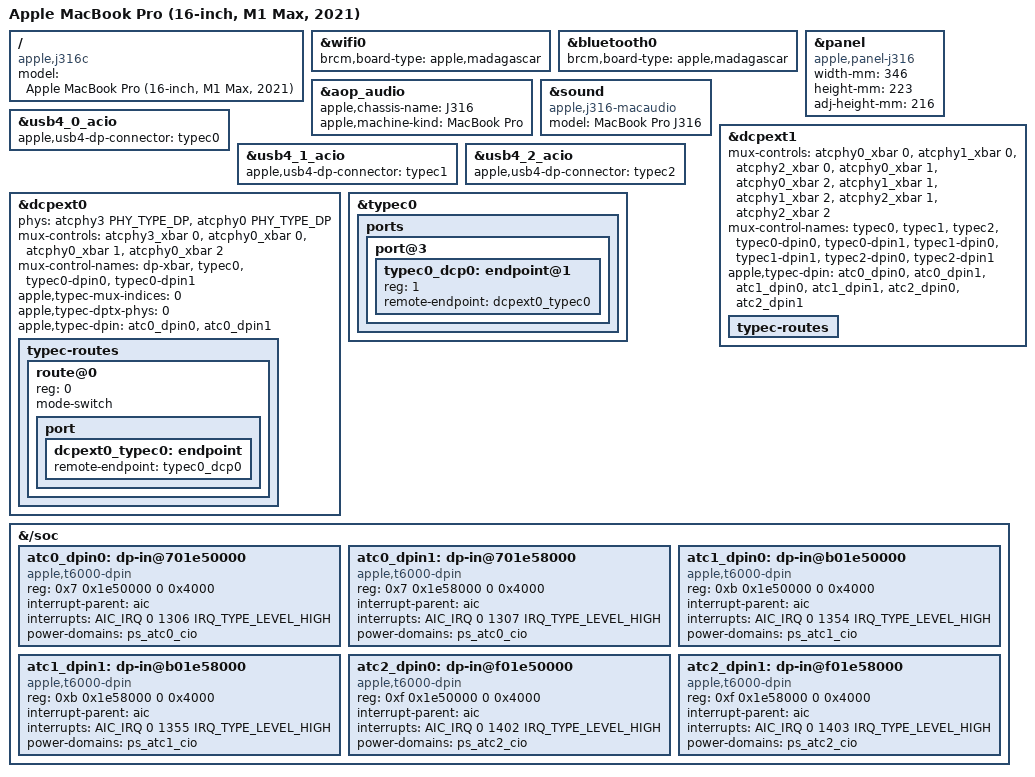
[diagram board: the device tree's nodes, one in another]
// SPDX-License-Identifier: GPL-2.0+ OR MIT
/*
 * MacBook Pro (16-inch, M1 Max, 2021)
 *
 * target-type: J316c
 *
 * Copyright The Asahi Linux Contributors
 */

/dts-v1/;

#include "t6001.dtsi"
#include "t600x-j314-j316.dtsi"

/ {
	compatible = "apple,j316c", "apple,t6001", "apple,arm-platform";
	model = "Apple MacBook Pro (16-inch, M1 Max, 2021)";
};

&wifi0 {
	brcm,board-type = "apple,madagascar";
};

&bluetooth0 {
	brcm,board-type = "apple,madagascar";
};

&panel {
	compatible = "apple,panel-j316", "apple,panel-mini-led", "apple,panel";
	width-mm = <346>;
	height-mm = <223>;
	adj-height-mm = <216>;
};

&aop_audio {
	apple,chassis-name = "J316";
	apple,machine-kind = "MacBook Pro";
};

&sound {
	compatible = "apple,j316-macaudio", "apple,macaudio";
	model = "MacBook Pro J316";
};

/* Experimental USB4 DP source routing; appledrm.usb4_dp gates activation. */
&dcpext1 {
	mux-controls = <&atcphy0_xbar 0>, <&atcphy1_xbar 0>, <&atcphy2_xbar 0>,
		       <&atcphy0_xbar 1>, <&atcphy0_xbar 2>,
		       <&atcphy1_xbar 1>, <&atcphy1_xbar 2>,
		       <&atcphy2_xbar 1>, <&atcphy2_xbar 2>;
	mux-control-names = "typec0", "typec1", "typec2",
			    "typec0-dpin0", "typec0-dpin1",
			    "typec1-dpin0", "typec1-dpin1",
			    "typec2-dpin0", "typec2-dpin1";
};

&usb4_0_acio { apple,usb4-dp-connector = <&typec0>; };
&usb4_1_acio { apple,usb4-dp-connector = <&typec1>; };
&usb4_2_acio { apple,usb4-dp-connector = <&typec2>; };

&dcpext1 {
	apple,typec-dpin = <&atc0_dpin0>, <&atc0_dpin1>,
			  <&atc1_dpin0>, <&atc1_dpin1>,
			  <&atc2_dpin0>, <&atc2_dpin1>;
};

/*
 * Experimental: also offer the dcpext0 pipeline (the one macOS uses for a
 * tunneled TS4 display) to Type-C port 0 (ATC0). HDMI stays on dcpext0.
 */
&dcpext0 {
	phys = <&atcphy3 PHY_TYPE_DP>, <&atcphy0 PHY_TYPE_DP>;
	phy-names = "dp-phy", "typec0";
	mux-controls = <&atcphy3_xbar 0>, <&atcphy0_xbar 0>,
		       <&atcphy0_xbar 1>, <&atcphy0_xbar 2>;
	mux-control-names = "dp-xbar", "typec0", "typec0-dpin0", "typec0-dpin1";
	apple,typec-mux-indices = <0>;
	apple,typec-dptx-phys = <0>;
	apple,typec-dpin = <&atc0_dpin0>, <&atc0_dpin1>;

	typec-routes {
		#address-cells = <1>;
		#size-cells = <0>;

		route@0 {
			reg = <0>;
			mode-switch;

			port {
				dcpext0_typec0: endpoint {
					remote-endpoint = <&typec0_dcp0>;
				};
			};
		};
	};
};

/*
 * Make dcpext0 the only pipeline offered to Type-C port 0 so the experiment
 * is deterministic: drop the dcpext1 route and its connector endpoint.
 */
&dcpext1 {
	typec-routes {
		/delete-node/ route@0;
	};
};

&typec0 {
	ports {
		port@3 {
			/delete-node/ endpoint@0;

			typec0_dcp0: endpoint@1 {
				reg = <1>;
				remote-endpoint = <&dcpext0_typec0>;
			};
		};
	};
};

&{/soc} {
	atc0_dpin0: dp-in@701e50000 {
		compatible = "apple,t6000-dpin";
		reg = <0x7 0x1e50000 0 0x4000>;
		interrupt-parent = <&aic>;
		interrupts = <AIC_IRQ 0 1306 IRQ_TYPE_LEVEL_HIGH>;
		power-domains = <&ps_atc0_cio>;
	};
	atc0_dpin1: dp-in@701e58000 {
		compatible = "apple,t6000-dpin";
		reg = <0x7 0x1e58000 0 0x4000>;
		interrupt-parent = <&aic>;
		interrupts = <AIC_IRQ 0 1307 IRQ_TYPE_LEVEL_HIGH>;
		power-domains = <&ps_atc0_cio>;
	};
	atc1_dpin0: dp-in@b01e50000 {
		compatible = "apple,t6000-dpin";
		reg = <0xb 0x1e50000 0 0x4000>;
		interrupt-parent = <&aic>;
		interrupts = <AIC_IRQ 0 1354 IRQ_TYPE_LEVEL_HIGH>;
		power-domains = <&ps_atc1_cio>;
	};
	atc1_dpin1: dp-in@b01e58000 {
		compatible = "apple,t6000-dpin";
		reg = <0xb 0x1e58000 0 0x4000>;
		interrupt-parent = <&aic>;
		interrupts = <AIC_IRQ 0 1355 IRQ_TYPE_LEVEL_HIGH>;
		power-domains = <&ps_atc1_cio>;
	};
	atc2_dpin0: dp-in@f01e50000 {
		compatible = "apple,t6000-dpin";
		reg = <0xf 0x1e50000 0 0x4000>;
		interrupt-parent = <&aic>;
		interrupts = <AIC_IRQ 0 1402 IRQ_TYPE_LEVEL_HIGH>;
		power-domains = <&ps_atc2_cio>;
	};
	atc2_dpin1: dp-in@f01e58000 {
		compatible = "apple,t6000-dpin";
		reg = <0xf 0x1e58000 0 0x4000>;
		interrupt-parent = <&aic>;
		interrupts = <AIC_IRQ 0 1403 IRQ_TYPE_LEVEL_HIGH>;
		power-domains = <&ps_atc2_cio>;
	};
};
